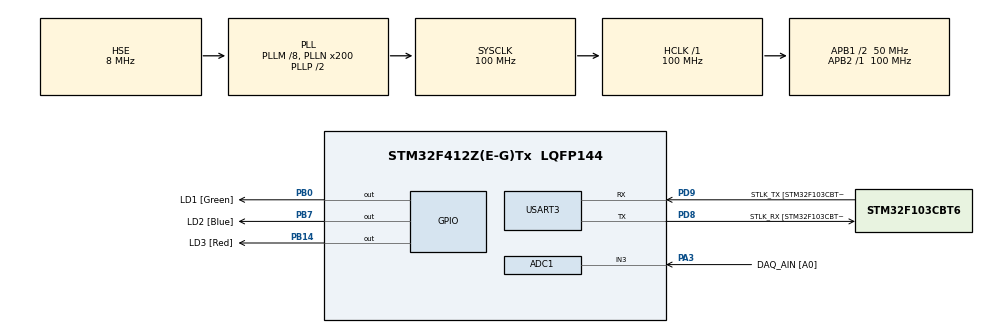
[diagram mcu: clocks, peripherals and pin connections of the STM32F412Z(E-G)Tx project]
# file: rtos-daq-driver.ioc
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ADC1.Channel-0\#ChannelRegularConversion=ADC_CHANNEL_3
ADC1.ClockPrescaler=ADC_CLOCK_SYNC_PCLK_DIV4
ADC1.EOCSelection=ADC_EOC_SINGLE_CONV
ADC1.ExternalTrigConv=ADC_EXTERNALTRIGCONV_T2_TRGO
ADC1.ExternalTrigConvEdge=ADC_EXTERNALTRIGCONVEDGE_RISING
ADC1.NbrOfConversionFlag=1
ADC1.Rank-0\#ChannelRegularConversion=1
ADC1.SamplingTime-0\#ChannelRegularConversion=ADC_SAMPLETIME_84CYCLES
ADC1.master=1
FREERTOS.Tasks01=dataProcTask,32,256,DataProcessingTask,As external,NULL,Dynamic,NULL,NULL;reportTask,8,512,ReportTask,As external,NULL,Dynamic,NULL,NULL
FREERTOS.configCHECK_FOR_STACK_OVERFLOW=2
FREERTOS.configUSE_MALLOC_FAILED_HOOK=1
Mcu.Family=STM32F4
Mcu.Name=STM32F412Z(E-G)Tx
Mcu.Package=LQFP144
NVIC.ADC_IRQn=true\:5\:0\:false\:false\:false\:true\:true\:true\:true
NVIC.PriorityGroup=NVIC_PRIORITYGROUP_4
NVIC.TIM6_IRQn=true\:15\:0\:false\:false\:true\:false\:false\:true\:true
NVIC.TimeBase=TIM6_IRQn
NVIC.TimeBaseIP=TIM6
PA13.GPIO_Label=TMS
PA13.Mode=Serial_Wire
PA13.Signal=SYS_JTMS-SWDIO
PA14.GPIO_Label=TCK
PA14.Mode=Serial_Wire
PA14.Signal=SYS_JTCK-SWCLK
PA3.GPIO_Label=DAQ_AIN [A0]
PA3.Signal=ADCx_IN3
PB0.GPIO_Label=LD1 [Green]
PB0.Signal=GPIO_Output
PB14.GPIO_Label=LD3 [Red]
PB14.Signal=GPIO_Output
PB3.GPIO_Label=SWO
PB3.Signal=SYS_JTDO-SWO
PB7.GPIO_Label=LD2 [Blue]
PB7.Signal=GPIO_Output
PD8.GPIO_Label=STLK_RX [STM32F103CBT6_PA3]
PD8.Mode=Asynchronous
PD8.Signal=USART3_TX
PD9.GPIO_Label=STLK_TX [STM32F103CBT6_PA2]
PD9.Mode=Asynchronous
PD9.Signal=USART3_RX
PH0\ -\ OSC_IN.GPIO_Label=MCO
PH0\ -\ OSC_IN.Mode=HSE-External-Clock-Source
PH0\ -\ OSC_IN.Signal=RCC_OSC_IN
PH1\ -\ OSC_OUT.Mode=HSE-External-Clock-Source
PH1\ -\ OSC_OUT.Signal=RCC_OSC_OUT
ProjectManager.HeapSize=0x200
ProjectManager.StackSize=0x400
ProjectManager.TargetToolchain=STM32CubeIDE
RCC.AHBFreq_Value=100000000
RCC.APB1CLKDivider=RCC_HCLK_DIV2
RCC.APB1Freq_Value=50000000
RCC.APB1TimFreq_Value=100000000
RCC.APB2Freq_Value=100000000
RCC.APB2TimFreq_Value=100000000
RCC.CortexFreq_Value=100000000
RCC.HCLKFreq_Value=100000000
RCC.HSE_VALUE=8000000
RCC.PLLM=8
RCC.PLLN=200
RCC.PLLP=RCC_PLLP_DIV2
RCC.PLLQ=4
RCC.PLLSourceVirtual=RCC_PLLSOURCE_HSE
RCC.SYSCLKFreq_VALUE=100000000
RCC.SYSCLKSource=RCC_SYSCLKSOURCE_PLLCLK
RCC.SYSCLKSourceVirtual=RCC_SYSCLKSOURCE_PLLCLK
RCC.USBFreq_Value=50000000
RCC.VCOOutputFreq_Value=200000000
SH.ADCx_IN3.0=ADC1_IN3,IN3
TIM2.Period=999
TIM2.Prescaler=99
TIM2.TIM_MasterOutputTrigger=TIM_TRGO_UPDATE
USART3.VirtualMode=VM_ASYNC
VP_FREERTOS_VS_CMSIS_V2.Mode=CMSIS_V2
VP_SYS_VS_tim6.Mode=TIM6
VP_TIM2_VS_ClockSourceINT.Mode=Internal
board=NUCLEO-F412ZG

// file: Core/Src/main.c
/* USER CODE BEGIN Header */
/**
  ******************************************************************************
  * @file           : main.c
  * @brief          : Main program body
  ******************************************************************************
  * @attention
  *
  * Copyright (c) 2026 STMicroelectronics.
  * All rights reserved.
  *
  * This software is licensed under terms that can be found in the LICENSE file
  * in the root directory of this software component.
  * If no LICENSE file comes with this software, it is provided AS-IS.
  *
  ******************************************************************************
  */
/* USER CODE END Header */
#include "main.h"
#include "cmsis_os.h"

/* USER CODE BEGIN Includes */
#include "daq.h"
#include "app_tasks.h"
/* USER CODE END Includes */

ADC_HandleTypeDef hadc1;

TIM_HandleTypeDef htim2;

UART_HandleTypeDef huart3;

/* Definitions for dataProcTask */
osThreadId_t dataProcTaskHandle;
const osThreadAttr_t dataProcTask_attributes = {
  .name = "dataProcTask",
  .stack_size = 256 * 4,
  .priority = (osPriority_t) osPriorityAboveNormal,
};
/* Definitions for reportTask */
osThreadId_t reportTaskHandle;
const osThreadAttr_t reportTask_attributes = {
  .name = "reportTask",
  .stack_size = 512 * 4,
  .priority = (osPriority_t) osPriorityLow,
};

void SystemClock_Config(void);
static void MX_GPIO_Init(void);
static void MX_ADC1_Init(void);
static void MX_TIM2_Init(void);
static void MX_USART3_UART_Init(void);
extern void DataProcessingTask(void *argument);
extern void ReportTask(void *argument);

int main(void)
{

  /* MCU Configuration--------------------------------------------------------*/

  /* Reset of all peripherals, Initializes the Flash interface and the Systick. */
  HAL_Init();

  /* Configure the system clock */
  SystemClock_Config();

  /* Initialize all configured peripherals */
  MX_GPIO_Init();
  MX_ADC1_Init();
  MX_TIM2_Init();
  MX_USART3_UART_Init();

  /* Init scheduler */
  osKernelInitialize();

  /* USER CODE BEGIN RTOS_SEMAPHORES */
  /* Ring buffer + binary semaphore of the ADC driver (statically allocated).
   * The ADC interrupts are enabled later by daq_start(), from the processing task. */
  daq_init();
  /* USER CODE END RTOS_SEMAPHORES */

  /* USER CODE BEGIN RTOS_QUEUES */
  /* Queue that carries the window statistics to the report task. */
  app_tasks_init();
  /* USER CODE END RTOS_QUEUES */

  /* Create the thread(s) */
  /* creation of dataProcTask */
  dataProcTaskHandle = osThreadNew(DataProcessingTask, NULL, &dataProcTask_attributes);

  /* creation of reportTask */
  reportTaskHandle = osThreadNew(ReportTask, NULL, &reportTask_attributes);

  /* Start scheduler */
  osKernelStart();

  /* We should never get here as control is now taken by the scheduler */

  /* Infinite loop */
  while (1)
  {

  }
}

void SystemClock_Config(void)
{
  RCC_OscInitTypeDef RCC_OscInitStruct = {0};
  RCC_ClkInitTypeDef RCC_ClkInitStruct = {0};

  /** Configure the main internal regulator output voltage
  */
  __HAL_RCC_PWR_CLK_ENABLE();
  __HAL_PWR_VOLTAGESCALING_CONFIG(PWR_REGULATOR_VOLTAGE_SCALE1);

  /** Initializes the RCC Oscillators according to the specified parameters
  * in the RCC_OscInitTypeDef structure.
  */
  RCC_OscInitStruct.OscillatorType = RCC_OSCILLATORTYPE_HSE;
  RCC_OscInitStruct.HSEState = RCC_HSE_BYPASS;
  RCC_OscInitStruct.PLL.PLLState = RCC_PLL_ON;
  RCC_OscInitStruct.PLL.PLLSource = RCC_PLLSOURCE_HSE;
  RCC_OscInitStruct.PLL.PLLM = 8;
  RCC_OscInitStruct.PLL.PLLN = 200;
  RCC_OscInitStruct.PLL.PLLP = RCC_PLLP_DIV2;
  RCC_OscInitStruct.PLL.PLLQ = 4;
  RCC_OscInitStruct.PLL.PLLR = 2;
  if (HAL_RCC_OscConfig(&RCC_OscInitStruct) != HAL_OK)
  {
    Error_Handler();
  }

  /** Initializes the CPU, AHB and APB buses clocks
  */
  RCC_ClkInitStruct.ClockType = RCC_CLOCKTYPE_HCLK|RCC_CLOCKTYPE_SYSCLK
                              |RCC_CLOCKTYPE_PCLK1|RCC_CLOCKTYPE_PCLK2;
  RCC_ClkInitStruct.SYSCLKSource = RCC_SYSCLKSOURCE_PLLCLK;
  RCC_ClkInitStruct.AHBCLKDivider = RCC_SYSCLK_DIV1;
  RCC_ClkInitStruct.APB1CLKDivider = RCC_HCLK_DIV2;
  RCC_ClkInitStruct.APB2CLKDivider = RCC_HCLK_DIV1;

  if (HAL_RCC_ClockConfig(&RCC_ClkInitStruct, FLASH_LATENCY_3) != HAL_OK)
  {
    Error_Handler();
  }
}

static void MX_ADC1_Init(void)
{

  ADC_ChannelConfTypeDef sConfig = {0};

  /** Configure the global features of the ADC (Clock, Resolution, Data Alignment and number of conversion)
  */
  hadc1.Instance = ADC1;
  hadc1.Init.ClockPrescaler = ADC_CLOCK_SYNC_PCLK_DIV4;
  hadc1.Init.Resolution = ADC_RESOLUTION_12B;
  hadc1.Init.ScanConvMode = DISABLE;
  hadc1.Init.ContinuousConvMode = DISABLE;
  hadc1.Init.DiscontinuousConvMode = DISABLE;
  hadc1.Init.ExternalTrigConvEdge = ADC_EXTERNALTRIGCONVEDGE_RISING;
  hadc1.Init.ExternalTrigConv = ADC_EXTERNALTRIGCONV_T2_TRGO;
  hadc1.Init.DataAlign = ADC_DATAALIGN_RIGHT;
  hadc1.Init.NbrOfConversion = 1;
  hadc1.Init.DMAContinuousRequests = DISABLE;
  hadc1.Init.EOCSelection = ADC_EOC_SINGLE_CONV;
  if (HAL_ADC_Init(&hadc1) != HAL_OK)
  {
    Error_Handler();
  }

  /** Configure for the selected ADC regular channel its corresponding rank in the sequencer and its sample time.
  */
  sConfig.Channel = ADC_CHANNEL_3;
  sConfig.Rank = 1;
  sConfig.SamplingTime = ADC_SAMPLETIME_84CYCLES;
  if (HAL_ADC_ConfigChannel(&hadc1, &sConfig) != HAL_OK)
  {
    Error_Handler();
  }

}

static void MX_TIM2_Init(void)
{

  TIM_ClockConfigTypeDef sClockSourceConfig = {0};
  TIM_MasterConfigTypeDef sMasterConfig = {0};

  htim2.Instance = TIM2;
  htim2.Init.Prescaler = 99;
  htim2.Init.CounterMode = TIM_COUNTERMODE_UP;
  htim2.Init.Period = 999;
  htim2.Init.ClockDivision = TIM_CLOCKDIVISION_DIV1;
  htim2.Init.AutoReloadPreload = TIM_AUTORELOAD_PRELOAD_DISABLE;
  if (HAL_TIM_Base_Init(&htim2) != HAL_OK)
  {
    Error_Handler();
  }
  sClockSourceConfig.ClockSource = TIM_CLOCKSOURCE_INTERNAL;
  if (HAL_TIM_ConfigClockSource(&htim2, &sClockSourceConfig) != HAL_OK)
  {
    Error_Handler();
  }
  sMasterConfig.MasterOutputTrigger = TIM_TRGO_UPDATE;
  sMasterConfig.MasterSlaveMode = TIM_MASTERSLAVEMODE_DISABLE;
  if (HAL_TIMEx_MasterConfigSynchronization(&htim2, &sMasterConfig) != HAL_OK)
  {
    Error_Handler();
  }

}

static void MX_USART3_UART_Init(void)
{

  huart3.Instance = USART3;
  huart3.Init.BaudRate = 115200;
  huart3.Init.WordLength = UART_WORDLENGTH_8B;
  huart3.Init.StopBits = UART_STOPBITS_1;
  huart3.Init.Parity = UART_PARITY_NONE;
  huart3.Init.Mode = UART_MODE_TX_RX;
  huart3.Init.HwFlowCtl = UART_HWCONTROL_NONE;
  huart3.Init.OverSampling = UART_OVERSAMPLING_16;
  if (HAL_UART_Init(&huart3) != HAL_OK)
  {
    Error_Handler();
  }

}

static void MX_GPIO_Init(void)
{
  GPIO_InitTypeDef GPIO_InitStruct = {0};

  /* GPIO Ports Clock Enable */
  __HAL_RCC_GPIOH_CLK_ENABLE();
  __HAL_RCC_GPIOA_CLK_ENABLE();
  __HAL_RCC_GPIOB_CLK_ENABLE();
  __HAL_RCC_GPIOD_CLK_ENABLE();

  /*Configure GPIO pin Output Level */
  HAL_GPIO_WritePin(GPIOB, LD1_Pin|LD3_Pin|LD2_Pin, GPIO_PIN_RESET);

  /*Configure GPIO pins : LD1_Pin LD3_Pin LD2_Pin */
  GPIO_InitStruct.Pin = LD1_Pin|LD3_Pin|LD2_Pin;
  GPIO_InitStruct.Mode = GPIO_MODE_OUTPUT_PP;
  GPIO_InitStruct.Pull = GPIO_NOPULL;
  GPIO_InitStruct.Speed = GPIO_SPEED_FREQ_LOW;
  HAL_GPIO_Init(GPIOB, &GPIO_InitStruct);

}

__weak void DataProcessingTask(void *argument)
{
  for(;;)
  {
    osDelay(1);
  }
}

void HAL_TIM_PeriodElapsedCallback(TIM_HandleTypeDef *htim)
{
  if (htim->Instance == TIM6)
  {
    HAL_IncTick();
  }
}

void Error_Handler(void)
{
  /* USER CODE BEGIN Error_Handler_Debug */
  /* Fatal error: stop everything and leave the red LED on. */
  __disable_irq();
  HAL_GPIO_WritePin(LD3_GPIO_Port, LD3_Pin, GPIO_PIN_SET);
  while (1)
  {
  }
  /* USER CODE END Error_Handler_Debug */
}

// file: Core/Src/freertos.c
/* USER CODE BEGIN Header */
/**
  ******************************************************************************
  * File Name          : freertos.c
  * Description        : Code for freertos applications
  ******************************************************************************
  * @attention
  *
  * Copyright (c) 2026 STMicroelectronics.
  * All rights reserved.
  *
  * This software is licensed under terms that can be found in the LICENSE file
  * in the root directory of this software component.
  * If no LICENSE file comes with this software, it is provided AS-IS.
  *
  ******************************************************************************
  */
/* USER CODE END Header */

#include "FreeRTOS.h"
#include "task.h"
#include "main.h"

/* Hook prototypes */
void vApplicationStackOverflowHook(xTaskHandle xTask, signed char *pcTaskName);
void vApplicationMallocFailedHook(void);

/* USER CODE BEGIN 4 */
void vApplicationStackOverflowHook(xTaskHandle xTask, signed char *pcTaskName)
{
   /* Called by the kernel (configCHECK_FOR_STACK_OVERFLOW = 2) when a task has
   overrun its stack. Memory may already be corrupted, so stop here. In the
   debugger, pcTaskName tells which task it was. */
   (void)xTask;
   (void)pcTaskName;
   Error_Handler();
}
/* USER CODE END 4 */

/* USER CODE BEGIN 5 */
void vApplicationMallocFailedHook(void)
{
   /* Called when pvPortMalloc() fails. Only task creation uses the FreeRTOS heap
   in this project (the semaphore and the queue are static), so this means
   configTOTAL_HEAP_SIZE is too small for the task stacks. */
   Error_Handler();
}
/* USER CODE END 5 */
